# hostmcu_aon_secure register map
Vendor: Texas Instruments
Peripheral module from a debugger description file (folder CC35X1E).
Registers are 32-bit, access per field, reset 0x0 unless marked. A register's access mark holds for its fields unless they carry their own. Offsets are as the file gives them; lines under a group give offsets from that group; [hi:lo] are bit positions; {n}, {i} and the like mark numbered series; 'fields as' and 'values as' point back to an identical list; <NAME> marks a mode.

## hostmcu_aon_secure
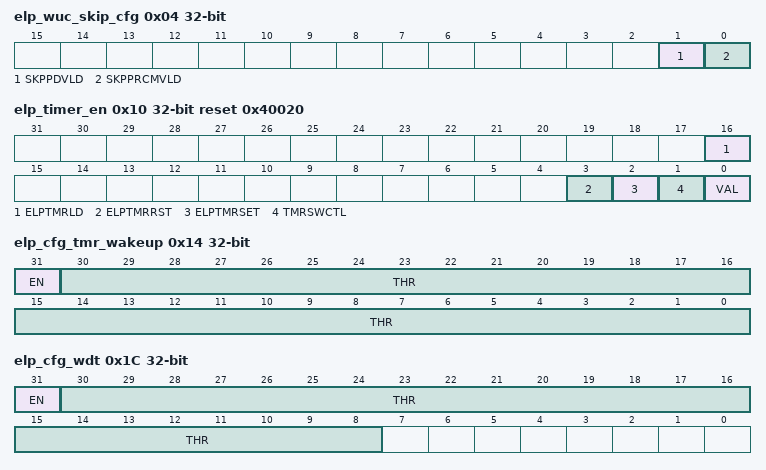
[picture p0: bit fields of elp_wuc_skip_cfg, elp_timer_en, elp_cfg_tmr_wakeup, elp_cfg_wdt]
0x04 elp_wuc_skip_cfg — Wake up Control Skip Configuration
  [1] SKPPDVLD rw — SKIP POWER DOMAIN VALID Enable skip precise duration for Power Domain if wake up event type is '0': '0' - don't skip '1' - skip
    0=DIS (Don't skip); 1=EN (Skip)
  [0] SKPPRCMVLD rw — SKIP PRCM VALID Enable skip precise duration for PRCM Shared UP if wake up event type is '0': '0' - don't skip '1' - skip
    0=DIS (Don't Skip); 1=EN (Skip)
0x08 host_elp_cfg_wicsense — Configure WIC SENSE
  [17:0] VAL rw — Field to control wake up source Set 1 - Enable wake up source. Set 0 - Disable wake up source. Bit 0 : ELP TMR Wake up request Bit 1 : GPIO wake up src 0 Bit 2 : GPIO wake up src 1 Bit 3 : doorbell 0 Bit 4 : doorbell 1 Bit 5 : doorbell 2 Bit 6 : doorbell 3 Bit 7 : doorbell 4 Bit 8 : doorbell 5 Bit 9 : doorbell 6 Bit 10 : doorbell 7 Bit 11 : nab_host_irq Bit 12 : ble_rfc_gpo_8_irq Bit 13 : RTC Bit 14 : DebugSS Csyspwrupreq Bit 15 : DebugSS Forceactive Bit 16 : secured_error_irq Bit 17 : core wdt irq Note: GPIO wakeup src 0 is AND of wakeup sources and GPIO wakup src 1 is OR of wakeup sources
    0=DIS (Disable wakeup source); 1=TMRREQ_EN (ELP timer wakeup request); 2=WUSRC0_EN (AND of wakeup sources); 4=WUSRC1_EN (OR of wakeup sources); 8=DRBL0_EN (Doorbell 0); 16=DRBL1_EN (Doorbell 1); 32=DRBL2_EN (Doorbell 2); 64=DRBL3_EN (Doorbell 3); 128=DRBL4_EN (Doorbell 4); 0x100=DRBL5_EN (Doorbell 5); 0x200=DRBL6_EN (Doorbell 6); 0x400=DRBL7_EN (Doorbell 7); 0x800=NAB_EN (NAB host irq); 0x1000=BLERFCGPO_EN (BLE RFC GPO 9 irq); 0x2000=RTC_EN; 0x4000=DBGPWRUP_EN (Debugss Csyspwrupreq); 0x8000=DBGFRCACT_EN (Debugss forecactive); 0x10000=SECERR_EN (Secure error irq); 0x20000=COREWDT_EN (Core WDT request)
0x0C host_elp_cfg_wakeup_type — ELP Wake-up Type Configuration. Register to configure wake up type
  [17:0] VAL rw — Field to configure wake up type Set 0 - Slow Wake up (precise WU). Set 1 - Fast Wake up (assume system is already active when event is triggered). Bit 0 : ELP TMR Wake up request Bit 1 : GPIO wake up src 0 Bit 2 : GPIO wake up src 1 Bit 3 : doorbell 0 Bit 4 : doorbell 1 Bit 5 : doorbell 2 Bit 6 : doorbell 3 Bit 7 : doorbell 4 Bit 8 : doorbell 5 Bit 9 : doorbell 6 Bit 10 : doorbell 7 Bit 11 : nab_host_irq Bit 12 : ble_rfc_gpo_8_irq Bit 13 : RTC Bit 14 : DebugSS Csyspwrupreq Bit 15 : DebugSS Forceactive Bit 16 : secured_error_irq Bit 17 : core wdt irq Note: GPIO wakeup src 0 is AND of wakeup sources and GPIO wakup src 1 is OR of wakeup sources
    0=SLOW (Slow wakeup(precise wakup)); 1=TMRREQ (Fast Wake up); 2=WUSRC0 (Fast Wake up); 4=WUSRC1 (Fast Wake up); 8=DRBL0 (Fast Wake up); 16=DRBL1 (Fast Wake up); 32=DRBL2 (Fast Wake up); 64=DRBL3 (Fast Wake up); 128=DRBL4 (Fast Wake up); 0x100=DRBL5 (Fast Wake up); 0x200=DRBL6 (Fast Wake up); 0x400=DRBL7 (Fast Wake up); 0x800=NAB (Fast Wake up); 0x1000=BLERFCGPO (Fast Wake up); 0x2000=RTC (Fast Wake up); 0x4000=DBGPWRUP (Fast Wake up); 0x8000=DBGFRCACT (Fast Wake up); 0x10000=SECERR (Fast Wake up); 0x20000=COREWDT (Fast Wake up)
0x10 elp_timer_en reset 0x40020 (reset mask 0xFFFEFFF0) — ELP Timer Enable. Register to configure ELP Timer enable
  [16] ELPTMRLD wo — ELP TIMER LOAD setting this bit will load the value 2 to the timer
  [3] ELPTMRRST rw — ELP TIMER RESET setting this bit will stop the timer
  [2] ELPTMRSET rw — ELP TIMER SET starts the timer
  [1] TMRSWCTL rw — Field to configure the type of timer control
    0=HW (Hardware control); 1=SW (Software control)
  [0] VAL ro — Field to enable ELP Timer
    0=DIS (Disable); 1=EN (Enable)
0x14 elp_cfg_tmr_wakeup rw — Timer Wake-up Configuration. Register to configure Timer wake up
  [31] EN — Field to enable timer wake up Set 1 - Enable BCN threshold IRQ. Set 0 - Otherwise. Timer is kicked upon moving from ACTIVE to POWER DOWN.
    0=DIS (otherwise); 1=EN (Enable BCN threshold IRQ)
  [30:0] THR — Field to configure the Threshold of timer wake up Upon reaching this value wake up event is generated towards the WUC (if not masked in WICSENSE). Resolution slow clock cycles. value must be greater than 1
0x18 elp_tmr_wakeup_req_clr — Timer Wake-up Request Clear. Register to configure timer wake up request
  [0] CLR wo — Field to clear timer wake up request. Set this bit to clear
0x1C elp_cfg_wdt reset not defined — Watch Dog Timer Configuration. Register to configure watchdog timer
  [31] EN rw — Field to enable watchdog timer
    0=DIS; 1=EN
  [30:8] THR rw — Field to configure watchdog timer threshold Upon reaching this value wake up event is generated towards the WUC (if not masked in WICSENSE). Resolution slow clock cycles (min val ~8ms). value must be greater than 1
0x20 elp_wdt_req_clr — Watch Dog Timer Request Clear. Register to clear watchdog timer request
  [0] CLR wo — Field to clear watchdog timer request. Set this bet to clear
0x28 elp_gpio_wakeup_and_irq rw reset 0xFFFFFFFF — GPIO Wake-up AND IRQ Configuration. Field to configure *GPIO* wake up AND *IRQ* 0 to 31
  [31:0] BM0T31 — Field to bit mask GPIO 0 to 31 select 0-31 GPIOs as wake up source.
0x2C elp_gpio_wakeup_or_irq rw reset 0xFFFFFFFF — GPIO Wake-up OR IRQ Configuration. Field to configure *GPIO* wake up OR gate *IRQ*
  fields as elp_gpio_wakeup_and_irq
0x30 elp_gpio_wakeup_and_irq_1 reset not defined — GPIO Wake-up AND IRQ Configuration. Field to configure *GPIO* wake up AND *IRQ* 32 to 44
  [12:0] BM32T44 rw — Field to bit mask 32 to 44 select 32-44 GPIOs as wake up source.
0x34 elp_gpio_wakeup_or_irq_1 reset not defined — GPIO Wake-up OR IRQ Configuration. Field to configure *GPIO* wake up OR *IRQ* 32 to 44
  fields as elp_gpio_wakeup_and_irq_1
0x38 elp_fast_clk_from_arm_cmd ro — Fast Clock From ARM Command
  [15:0] CMD — Command Latched counter value reflecting the number of fast clocks (host_clk) from rise of SLEEPDEEP indication until ELP WUC start power down sequence. This value should capture the uncertainty of 2-3 slow clocks of synchronization of ARM CMD
0x3C elp_sleep_time_slow ro — Sleep Time Slow Clock. Register for sleep time on slow clock
  [31:0] CLK — Sleep time value from last ELP sleep entry (slow clock synced ARM CMD). Slow Clock - Reflects the number of slow clocks in ELP timer.
0x40 elp_sleep_time_fast ro — Sleep Time Fast Clock. Register for sleep time on fast clock
  [10:0] CLK — Sleep time value from last ELP sleep entry (slow clock synced ARM CMD). Fast Clock - Reflects the number of fast clocks from last Slow clock rise until OCP Read. Note, fast counter value is latched upon OCP Read of ELP_SLEEP_TIME_SLOW. Counts up t0 51 microsecond.
0x4C elp_wakeup_req ro — Wake up Request Status
  [17:0] VAL — Field to show the event request Bit 0 : ELP TMR Wake up request Bit 1 : GPIO wake up src 0 Bit 2 : GPIO wake up src 1 Bit 3 : doorbell 0 Bit 4 : doorbell 1 Bit 5 : doorbell 2 Bit 6 : doorbell 3 Bit 7 : doorbell 4 Bit 8 : doorbell 5 Bit 9 : doorbell 6 Bit 10 : doorbell 7 Bit 11 : nab_host_irq Bit 12 : ble_rfc_gpo_8_irq Bit 13 : RTC Bit 14 : DebugSS Csyspwrupreq Bit 15 : DebugSS Force-active Bit 16 : secured_error_irq Bit 17 : core wdt irq Note: GPIO wakeup src 0 is AND of wakeup sources and GPIO wakup src 1 is OR of wakeup sources
    0=CLEAR (No event request); 1=TMRREQ (ELP timer wakeup request); 2=WUSRC0 (AND of wakeup sources); 4=WUSRC1 (OR of wakeup sources); 8=DRBL0 (Doorbell 0); 16=DRBL1 (Doorbell 1); 32=DRBL2 (Doorbell 2); 64=DRBL3 (Doorbell 3); 128=DRBL4 (Doorbell 4); 0x100=DRBL5 (Doorbell 5); 0x200=DRBL6 (Doorbell 6); 0x400=DRBL7 (Doorbell 7); 0x800=NAB (NAB host irq); 0x1000=BLERFCGPO (BLE RFC GPO 9 irq); 0x2000=RTC; 0x4000=DBGPWRUP (Debugss Csyspwrupreq); 0x8000=DBGFRCACT (Debugss forecactive); 0x10000=SECERR (Secure error irq); 0x20000=COREWDT (Core WDT request)
0x50 host_ospi_ref_clk reset not defined — OSPI Reference Clock. Field to select the OSPI reference clock
  [0] SEL rw — SELECTOR '0' - default host clk div2 '1' host clk div 4
    0=Host clock div2; 1=Host clock div4
0x5C host_wuc_state ro reset 0x24 — Wake-up Control State. Register for Host wake up state
  [2:0] STA — Field showing the host wake up state 3'b000 - PD_PWR_DN 3'b001 - SHARED_UP 3'b010 - PD_PWR_UP 3'b011 - ACTIVE 3'b100 - DEEPSLEEP
    0=RD_0 (PD power down); 1=RD_1 (Shared domain up); 2=RD_2 (PD power up); 3=RD_3 (Active)
